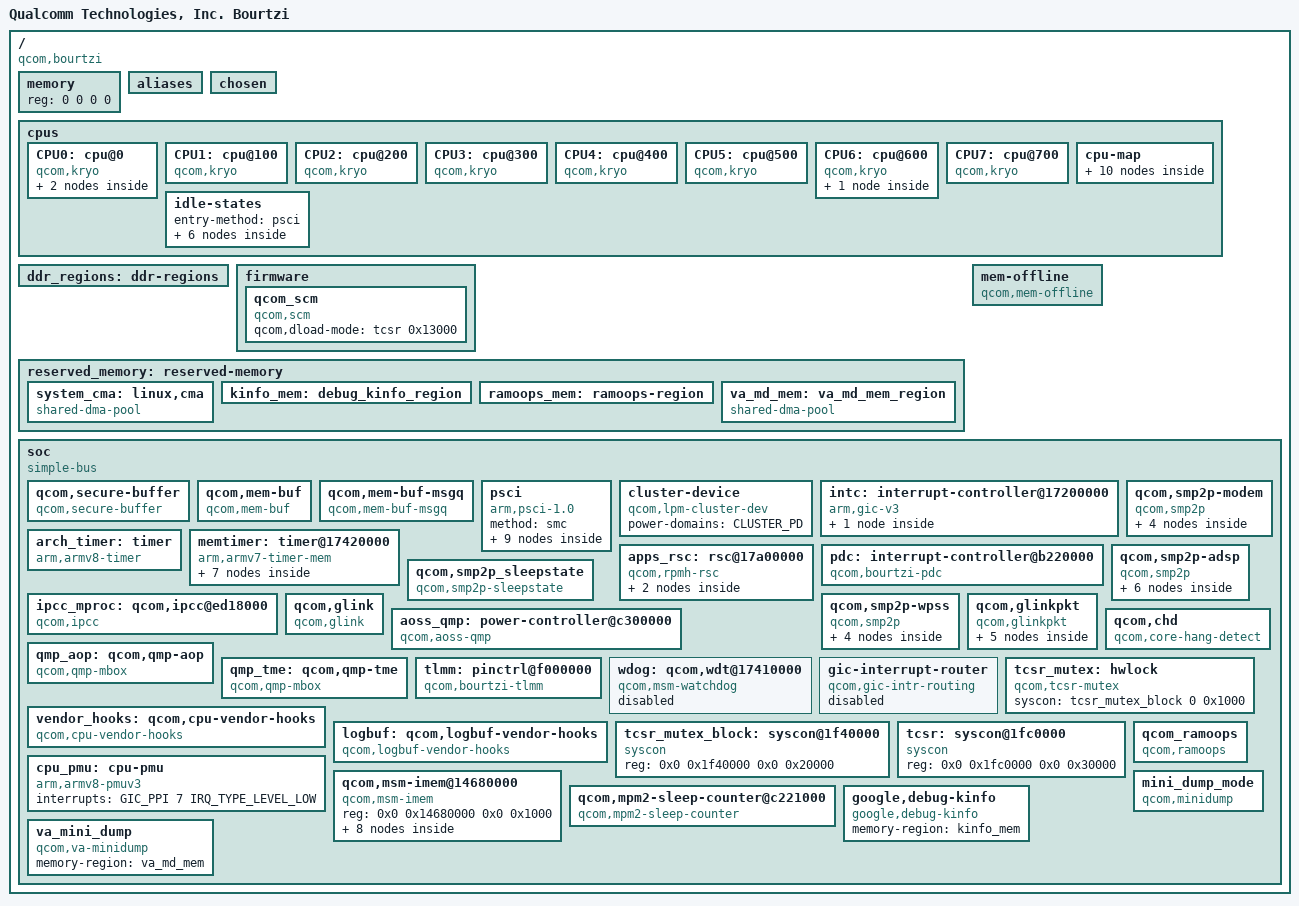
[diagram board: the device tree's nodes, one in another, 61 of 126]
// SPDX-License-Identifier: BSD-3-Clause
/*
 * Copyright (c) Qualcomm Technologies, Inc. and/or its subsidiaries.
 */

#include <dt-bindings/interrupt-controller/arm-gic.h>
#include <dt-bindings/soc/qcom,ipcc.h>
#include <dt-bindings/soc/qcom,rpmh-rsc.h>

/ {
	model = "Qualcomm Technologies, Inc. Bourtzi";
	compatible = "qcom,bourtzi";
	qcom,msm-id = <776 0x10000>;
	interrupt-parent = <&intc>;

	#address-cells = <2>;
	#size-cells = <2>;
	memory { device_type = "memory"; reg = <0 0 0 0>; };

	aliases: aliases { };

	chosen: chosen {
		bootargs = "nokaslr kpti=0 log_buf_len=512K earlycon swiotlb=0 kasan=off cgroup_disable=pressure cgroup.memory=nokmem,nosocket disable_dma32=on page_poison=on restrict_cma_redirect=false no-steal-acc android_arch_task_struct_size=512 sysctl.kernel.sched_pelt_multiplier=4 irqaffinity=0-5 cpufreq.default_governor=performance loop.max_part=7 fw_devlink.strict=1 rcupdate.rcu_expedited=1 rcu_nocbs=0-7 printk.console_no_auto_verbose=1 sysctl.kernel.panic_on_rcu_stall=1 ftrace_dump_on_oops slub_debug=-";
	};

	cpus {
		#address-cells = <2>;
		#size-cells = <0>;

		CPU0: cpu@0 {
			device_type = "cpu";
			compatible = "qcom,kryo";
			reg = <0x0 0x0>;
			capacity-dmips-mhz = <1024>;
			dynamic-power-coefficient = <100>;
			enable-method = "psci";
			cpu-idle-states = <&SILVER_CPU_OFF &SILVER_CPU_RAIL_OFF>;
			power-domains = <&CPU_PD0>;
			power-domain-names = "psci";
			next-level-cache = <&L2_0>;

			L2_0: l2-cache {
				compatible = "arm,arch-cache";
				cache-level = <2>;
				next-level-cache = <&L3_0>;

				L3_0: l3-cache {
					compatible = "arm,arch-cache";
					cache-level = <3>;
				};
			};
		};

		CPU1: cpu@100 {
			device_type = "cpu";
			compatible = "qcom,kryo";
			reg = <0x0 0x100>;
			capacity-dmips-mhz = <1024>;
			dynamic-power-coefficient = <100>;
			enable-method = "psci";
			cpu-idle-states = <&SILVER_CPU_OFF &SILVER_CPU_RAIL_OFF>;
			power-domains = <&CPU_PD1>;
			power-domain-names = "psci";
			next-level-cache = <&L2_0>;
		};

		CPU2: cpu@200 {
			device_type = "cpu";
			compatible = "qcom,kryo";
			reg = <0x0 0x200>;
			capacity-dmips-mhz = <1024>;
			dynamic-power-coefficient = <100>;
			enable-method = "psci";
			cpu-idle-states = <&SILVER_CPU_OFF &SILVER_CPU_RAIL_OFF>;
			power-domains = <&CPU_PD2>;
			power-domain-names = "psci";
			next-level-cache = <&L2_0>;
		};

		CPU3: cpu@300 {
			device_type = "cpu";
			compatible = "qcom,kryo";
			reg = <0x0 0x300>;
			capacity-dmips-mhz = <1024>;
			dynamic-power-coefficient = <100>;
			enable-method = "psci";
			cpu-idle-states = <&SILVER_CPU_OFF &SILVER_CPU_RAIL_OFF>;
			power-domains = <&CPU_PD3>;
			power-domain-names = "psci";
			next-level-cache = <&L2_0>;
		};

		CPU4: cpu@400 {
			device_type = "cpu";
			compatible = "qcom,kryo";
			reg = <0x0 0x400>;
			capacity-dmips-mhz = <1024>;
			dynamic-power-coefficient = <100>;
			enable-method = "psci";
			cpu-idle-states = <&SILVER_CPU_OFF &SILVER_CPU_RAIL_OFF>;
			power-domains = <&CPU_PD4>;
			power-domain-names = "psci";
			next-level-cache = <&L2_0>;
		};

		CPU5: cpu@500 {
			device_type = "cpu";
			compatible = "qcom,kryo";
			reg = <0x0 0x500>;
			capacity-dmips-mhz = <1024>;
			dynamic-power-coefficient = <100>;
			enable-method = "psci";
			cpu-idle-states = <&SILVER_CPU_OFF &SILVER_CPU_RAIL_OFF>;
			power-domains = <&CPU_PD5>;
			power-domain-names = "psci";
			next-level-cache = <&L2_0>;
		};

		CPU6: cpu@600 {
			device_type = "cpu";
			compatible = "qcom,kryo";
			reg = <0x0 0x600>;
			capacity-dmips-mhz = <1945>;
			dynamic-power-coefficient = <483>;
			enable-method = "psci";
			cpu-idle-states = <&GOLD_CPU_OFF &GOLD_CPU_RAIL_OFF>;
			power-domains = <&CPU_PD6>;
			power-domain-names = "psci";
			next-level-cache = <&L2_6>;

			L2_6: l2-cache {
				compatible = "arm,arch-cache";
				cache-level = <2>;
				next-level-cache = <&L3_0>;
			};
		};

		CPU7: cpu@700 {
			device_type = "cpu";
			compatible = "qcom,kryo";
			reg = <0x0 0x700>;
			capacity-dmips-mhz = <1945>;
			dynamic-power-coefficient = <483>;
			enable-method = "psci";
			cpu-idle-states = <&GOLD_CPU_OFF &GOLD_CPU_RAIL_OFF>;
			power-domains = <&CPU_PD7>;
			power-domain-names = "psci";
			next-level-cache = <&L2_6>;
		};

		cpu-map {

			cluster0 {

				core0 {
					cpu = <&CPU0>;
				};

				core1 {
					cpu = <&CPU1>;
				};

				core2 {
					cpu = <&CPU2>;
				};

				core3 {
					cpu = <&CPU3>;
				};

				core4 {
					cpu = <&CPU4>;
				};

				core5 {
					cpu = <&CPU5>;
				};
			};

			cluster1 {

				core0 {
					cpu = <&CPU6>;
				};

				core1 {
					cpu = <&CPU7>;
				};
			};
		};

		idle-states {
			entry-method = "psci";

			SILVER_CPU_OFF: silver-c3 {  /* C3 */
				compatible = "arm,idle-state";
				idle-state-name = "pc";
				entry-latency-us = <350>;
				exit-latency-us = <900>;
				min-residency-us = <1774>;
				arm,psci-suspend-param = <0x40000003>;
				local-timer-stop;
			};

			SILVER_CPU_RAIL_OFF: silver-c4 {  /* C4 */
				compatible = "arm,idle-state";
				idle-state-name = "rail-pc";
				entry-latency-us = <800>;
				exit-latency-us = <750>;
				min-residency-us = <4090>;
				arm,psci-suspend-param = <0x40000004>;
				local-timer-stop;
			};

			GOLD_CPU_OFF: gold-c3 {  /* C3 */
				compatible = "arm,idle-state";
				idle-state-name = "pc";
				entry-latency-us = <400>;
				exit-latency-us = <1550>;
				min-residency-us = <2207>;
				arm,psci-suspend-param = <0x40000003>;
				local-timer-stop;
			};

			GOLD_CPU_RAIL_OFF: gold-c4 {  /* C4 */
				compatible = "arm,idle-state";
				idle-state-name = "rail-pc";
				entry-latency-us = <600>;
				exit-latency-us = <1550>;
				min-residency-us = <4791>;
				arm,psci-suspend-param = <0x40000004>;
				local-timer-stop;
			};

			CLUSTER_OFF: cluster-d4 { /* D4 */
				compatible = "domain-idle-state";
				idle-state-name = "l3-off";
				entry-latency-us = <1050>;
				exit-latency-us = <2500>;
				min-residency-us = <5309>;
				arm,psci-suspend-param = <0x41000044>;
			};

			CX_RET: cx-ret { /* Cx Ret */
				compatible = "domain-idle-state";
				idle-state-name = "cx-ret";
				entry-latency-us = <1561>;
				exit-latency-us = <2801>;
				min-residency-us = <8550>;
				arm,psci-suspend-param = <0x41003344>;
			};
		};
	};

	ddr_regions: ddr-regions { };

	firmware: firmware { };

	reserved_memory: reserved-memory { };

	mem-offline {
		compatible = "qcom,mem-offline";
		offline-sizes = <0x2 0xc0000000 0x1 0x0>;
		granule = <512>;
		qcom,qmp = <&aoss_qmp>;
	};

	soc: soc { };
};

&firmware {
	qcom_scm: qcom_scm {
		compatible = "qcom,scm";
		qcom,dload-mode = <&tcsr 0x13000>;
	};
};

#include "bourtzi-reserved-memory.dtsi"
#include "msm-arm-smmu-bourtzi.dtsi"
#include "bourtzi-dma-heaps.dtsi"

&reserved_memory {
	#address-cells = <2>;
	#size-cells = <2>;
	ranges;

	/* global autoconfigured region for contiguous allocations */
	system_cma: linux,cma {
		compatible = "shared-dma-pool";
		alloc-ranges = <0x0 0x00000000 0x0 0xffffffff>;
		reusable;
		alignment = <0x0 0x400000>;
		size = <0x0 0x2400000>;
		linux,cma-default;
	};

	kinfo_mem: debug_kinfo_region {
		alloc-ranges = <0x0 0x00000000 0xffffffff 0xffffffff>;
		size = <0x0 0x1000>;
		no-map;
	};

	ramoops_mem: ramoops-region {
		alloc-ranges = <0x1 0x00000000 0xfffffffe 0xffffffff>;
		size = <0x0 0x200000>;
		no-map;
	};

	va_md_mem: va_md_mem_region {
		compatible = "shared-dma-pool";
		alloc-ranges = <0x0 0x00000000 0x0 0xffffffff>;
		reusable;
		size = <0 0x1000000>;
	};
};

&soc {
	#address-cells = <2>;
	#size-cells = <2>;
	ranges = <0 0 0 0 0x10 0>;
	compatible = "simple-bus";

	qcom,secure-buffer {
		compatible = "qcom,secure-buffer";
	};

	qcom,mem-buf {
		compatible = "qcom,mem-buf";
		qcom,mem-buf-capabilities = "supplier";
		qcom,vmid = <3>;
	};

	qcom,mem-buf-msgq {
		compatible = "qcom,mem-buf-msgq";
	};

	psci: psci {
		compatible = "arm,psci-1.0";
		method = "smc";

		CPU_PD0: cpu-pd0 {
			#power-domain-cells = <0>;
			power-domains = <&CLUSTER_PD>;
		};

		CPU_PD1: cpu-pd1 {
			#power-domain-cells = <0>;
			power-domains = <&CLUSTER_PD>;
		};

		CPU_PD2: cpu-pd2 {
			#power-domain-cells = <0>;
			power-domains = <&CLUSTER_PD>;
		};

		CPU_PD3: cpu-pd3 {
			#power-domain-cells = <0>;
			power-domains = <&CLUSTER_PD>;
		};

		CPU_PD4: cpu-pd4 {
			#power-domain-cells = <0>;
			power-domains = <&CLUSTER_PD>;
		};

		CPU_PD5: cpu-pd5 {
			#power-domain-cells = <0>;
			power-domains = <&CLUSTER_PD>;
		};

		CPU_PD6: cpu-pd6 {
			#power-domain-cells = <0>;
			power-domains = <&CLUSTER_PD>;
		};

		CPU_PD7: cpu-pd7 {
			#power-domain-cells = <0>;
			power-domains = <&CLUSTER_PD>;
		};

		CLUSTER_PD: cluster-pd {
			#power-domain-cells = <0>;
			domain-idle-states = <&CLUSTER_OFF &CX_RET>;
		};
	};

	cluster-device {
		compatible = "qcom,lpm-cluster-dev";
		power-domains = <&CLUSTER_PD>;
	};

	intc: interrupt-controller@17200000 {
		compatible = "arm,gic-v3";
		#interrupt-cells = <3>;
		interrupt-controller;
		#redistributor-regions = <1>;
		redistributor-stride = <0x0 0x20000>;
		reg = <0x0 0x17200000 0x0 0x10000>,	/* GICD */
		      <0x0 0x17260000 0x0 0x100000>;	/* GICR * 8 */
		interrupts = <GIC_PPI 9 IRQ_TYPE_LEVEL_LOW>;

		#address-cells = <1>;
		#size-cells = <1>;
		ranges;
		gic_its: msi-controller@17240000 {
			compatible = "arm,gic-v3-its";
			msi-controller;
			#msi-cells = <1>;
			reg = <0x17240000 0x20000>;
		};
	};

	arch_timer: timer {
		compatible = "arm,armv8-timer";
		interrupts = <GIC_PPI 13 (GIC_CPU_MASK_SIMPLE(8) | IRQ_TYPE_LEVEL_LOW)>,
			     <GIC_PPI 14 (GIC_CPU_MASK_SIMPLE(8) | IRQ_TYPE_LEVEL_LOW)>,
			     <GIC_PPI 11 (GIC_CPU_MASK_SIMPLE(8) | IRQ_TYPE_LEVEL_LOW)>,
			     <GIC_PPI 10 (GIC_CPU_MASK_SIMPLE(8) | IRQ_TYPE_LEVEL_LOW)>;
		clock-frequency = <19200000>;
	};

	memtimer: timer@17420000 {
		compatible = "arm,armv7-timer-mem";
		reg = <0x0 0x17420000 0x0 0x1000>;
		clock-frequency = <19200000>;
		#address-cells = <1>;
		#size-cells = <1>;
		ranges;

		frame@17421000 {
			frame-number = <0>;
			interrupts = <GIC_SPI 8 IRQ_TYPE_LEVEL_HIGH>,
				     <GIC_SPI 6 IRQ_TYPE_LEVEL_HIGH>;
			reg = <0x17421000 0x1000>,
			      <0x17422000 0x1000>;
		};

		frame@17423000 {
			frame-number = <1>;
			interrupts = <GIC_SPI 9 IRQ_TYPE_LEVEL_HIGH>;
			reg = <0x17423000 0x1000>;
			status = "disabled";
		};

		frame@17425000 {
			frame-number = <2>;
			interrupts = <GIC_SPI 10 IRQ_TYPE_LEVEL_HIGH>;
			reg = <0x17425000 0x1000>;
			status = "disabled";
		};

		frame@17427000 {
			frame-number = <3>;
			interrupts = <GIC_SPI 11 IRQ_TYPE_LEVEL_HIGH>;
			reg = <0x17427000 0x1000>;
			status = "disabled";
		};

		frame@17429000 {
			frame-number = <4>;
			interrupts = <GIC_SPI 12 IRQ_TYPE_LEVEL_HIGH>;
			reg = <0x17429000 0x1000>;
			status = "disabled";
		};

		frame@1742b000 {
			frame-number = <5>;
			interrupts = <GIC_SPI 13 IRQ_TYPE_LEVEL_HIGH>;
			reg = <0x1742b000 0x1000>;
			status = "disabled";
		};

		frame@1742d000 {
			frame-number = <6>;
			interrupts = <GIC_SPI 14 IRQ_TYPE_LEVEL_HIGH>;
			reg = <0x1742d000 0x1000>;
			status = "disabled";
		};
	};

	apps_rsc: rsc@17a00000 {
		label = "apps_rsc";
		compatible = "qcom,rpmh-rsc";
		reg = <0x0 0x17a00000 0x0 0x10000>,
		      <0x0 0x17a10000 0x0 0x10000>,
		      <0x0 0x17a20000 0x0 0x10000>;
		reg-names = "drv-0", "drv-1", "drv-2";
		qcom,drv-count = <3>;
		interrupts = <GIC_SPI 3 IRQ_TYPE_LEVEL_HIGH>,
			     <GIC_SPI 4 IRQ_TYPE_LEVEL_HIGH>,
			     <GIC_SPI 5 IRQ_TYPE_LEVEL_HIGH>;
		power-domains = <&CLUSTER_PD>;

		apps_rsc_drv2: drv@2 {
			qcom,drv-id = <2>;
			qcom,tcs-offset = <0xd00>;
			qcom,tcs-distance = <0x2a0>;

			channel@0 {
				 qcom,tcs-config = <ACTIVE_TCS    2>,
						   <SLEEP_TCS     3>,
						   <WAKE_TCS      3>,
						   <CONTROL_TCS   0>,
						   <FAST_PATH_TCS 0>;
			};
		};
	};

	pdc: interrupt-controller@b220000 {
		compatible = "qcom,bourtzi-pdc", "qcom,pdc";
		reg = <0x0 0xb220000 0x0 0x10000>, <0x0 0x174000f0 0x0 0x64>;
		qcom,pdc-ranges = <0 480 94>, <94 609 31>, <125 63 1>,
				  <126 716 12>;
		#interrupt-cells = <2>;
		interrupt-parent = <&intc>;
		interrupt-controller;
	};

	ipcc_mproc: qcom,ipcc@ed18000 {
		compatible = "qcom,ipcc";
		reg = <0x0 0xed18000 0x0 0x1000>;
		interrupts = <GIC_SPI 229 IRQ_TYPE_LEVEL_HIGH>;
		interrupt-controller;
		#interrupt-cells = <3>;
		#mbox-cells = <2>;
	};

	qcom,smp2p-modem {
		compatible = "qcom,smp2p";
		qcom,smem = <435>, <428>;
		interrupt-parent = <&ipcc_mproc>;
		interrupts = <IPCC_CLIENT_MPSS IPCC_MPROC_SIGNAL_SMP2P
				IRQ_TYPE_EDGE_RISING>;
		mboxes = <&ipcc_mproc IPCC_CLIENT_MPSS IPCC_MPROC_SIGNAL_SMP2P>;
		qcom,local-pid = <0>;
		qcom,remote-pid = <1>;

		modem_smp2p_out: master-kernel {
			qcom,entry-name = "master-kernel";
			#qcom,smem-state-cells = <1>;
		};

		modem_smp2p_in: slave-kernel {
			qcom,entry-name = "slave-kernel";
			interrupt-controller;
			#interrupt-cells = <2>;
		};

		smp2p_ipa_1_out: qcom,smp2p-ipa-1-out {
			qcom,entry-name = "ipa";
			#qcom,smem-state-cells = <1>;
		};

		/* ipa - inbound entry from mss */
		smp2p_ipa_1_in: qcom,smp2p-ipa-1-in {
			qcom,entry-name = "ipa";
			interrupt-controller;
			#interrupt-cells = <2>;
		};
	};

	qcom,smp2p-adsp {
		compatible = "qcom,smp2p";
		qcom,smem = <443>, <429>;
		interrupt-parent = <&ipcc_mproc>;
		interrupts = <IPCC_CLIENT_LPASS IPCC_MPROC_SIGNAL_SMP2P
			      IRQ_TYPE_EDGE_RISING>;
		mboxes = <&ipcc_mproc IPCC_CLIENT_LPASS
			  IPCC_MPROC_SIGNAL_SMP2P>;
		qcom,local-pid = <0>;
		qcom,remote-pid = <2>;

		adsp_smp2p_out: master-kernel {
			qcom,entry-name = "master-kernel";
			#qcom,smem-state-cells = <1>;
		};

		adsp_smp2p_in: slave-kernel {
			qcom,entry-name = "slave-kernel";
			interrupt-controller;
			#interrupt-cells = <2>;
		};

		sleepstate_smp2p_out: sleepstate-out {
			qcom,entry-name = "sleepstate";
			#qcom,smem-state-cells = <1>;
		};

		sleepstate_smp2p_in: qcom,sleepstate-in {
			qcom,entry-name = "sleepstate_see";
			interrupt-controller;
			#interrupt-cells = <2>;
		};

		smp2p_rdbg2_out: qcom,smp2p-rdbg2-out {
			qcom,entry-name = "rdbg";
			#qcom,smem-state-cells = <1>;
		};

		smp2p_rdbg2_in: qcom,smp2p-rdbg2-in {
			qcom,entry-name = "rdbg";
			interrupt-controller;
			#interrupt-cells = <2>;
		};
	};

	qcom,smp2p_sleepstate {
		compatible = "qcom,smp2p-sleepstate";
		qcom,smem-states = <&sleepstate_smp2p_out 0>;
		interrupt-parent = <&sleepstate_smp2p_in>;
		interrupts = <0 0>;
		interrupt-names = "smp2p-sleepstate-in";
	};

	qcom,smp2p-wpss {
		compatible = "qcom,smp2p";
		qcom,smem = <617>, <616>;
		interrupt-parent = <&ipcc_mproc>;
		interrupts = <IPCC_CLIENT_WPSS IPCC_MPROC_SIGNAL_SMP2P
			IRQ_TYPE_EDGE_RISING>;
		mboxes = <&ipcc_mproc IPCC_CLIENT_WPSS IPCC_MPROC_SIGNAL_SMP2P>;
		qcom,local-pid = <0>;
		qcom,remote-pid = <13>;

		wpss_smp2p_out: master-kernel {
			qcom,entry-name = "master-kernel";
			#qcom,smem-state-cells = <1>;
		};

		wpss_smp2p_in: slave-kernel {
			qcom,entry-name = "slave-kernel";
			interrupt-controller;
			#interrupt-cells = <2>;
		};

		smp2p_wlan_1_in: qcom,smp2p-wlan-1-in {
			qcom,entry-name = "wlan";
			interrupt-controller;
			#interrupt-cells = <2>;
		};

		smp2p_wlan_1_out: qcom,smp2p-wlan-1-out {
			qcom,entry-name = "wlan";
			#qcom,smem-state-cells = <1>;
		};
	};

	qcom,glinkpkt {
		compatible = "qcom,glinkpkt";

		qcom,glinkpkt-at-mdm0 {
			qcom,glinkpkt-edge = "mpss";
			qcom,glinkpkt-ch-name = "DS";
			qcom,glinkpkt-dev-name = "at_mdm0";
		};

		qcom,glinkpkt-data40-cntl {
			qcom,glinkpkt-edge = "mpss";
			qcom,glinkpkt-ch-name = "DATA40_CNTL";
			qcom,glinkpkt-dev-name = "smdcntl8";
		};

		qcom,glinkpkt-data1 {
			qcom,glinkpkt-edge = "mpss";
			qcom,glinkpkt-ch-name = "DATA1";
			qcom,glinkpkt-dev-name = "smd7";
		};

		qcom,glinkpkt-data4 {
			qcom,glinkpkt-edge = "mpss";
			qcom,glinkpkt-ch-name = "DATA4";
			qcom,glinkpkt-dev-name = "smd8";
		};

		qcom,glinkpkt-data11 {
			qcom,glinkpkt-edge = "mpss";
			qcom,glinkpkt-ch-name = "DATA11";
			qcom,glinkpkt-dev-name = "smd11";
		};
	};

	qcom,glink {
		compatible = "qcom,glink";
	};

	aoss_qmp: power-controller@c300000 {
		compatible = "qcom,aoss-qmp";
		reg = <0x0 0xc300000 0x0 0x400>;
		interrupt-parent = <&ipcc_mproc>;
		interrupts = <IPCC_CLIENT_AOP
			IPCC_MPROC_SIGNAL_GLINK_QMP
			IRQ_TYPE_EDGE_RISING>;
		mboxes = <&ipcc_mproc IPCC_CLIENT_AOP
			IPCC_MPROC_SIGNAL_GLINK_QMP>;

		#power-domain-cells = <1>;
		#clock-cells = <0>;
	};

	qmp_aop: qcom,qmp-aop {
		compatible = "qcom,qmp-mbox";
		qcom,qmp = <&aoss_qmp>;
		label = "aop";
		#mbox-cells = <1>;
	};

	qmp_tme: qcom,qmp-tme {
		compatible = "qcom,qmp-mbox";
		qcom,remote-pid = <14>;
		mboxes = <&ipcc_mproc IPCC_CLIENT_TME
				IPCC_MPROC_SIGNAL_GLINK_QMP>;
		mbox-names = "tme_qmp";
		interrupt-parent = <&ipcc_mproc>;
		interrupts = <IPCC_CLIENT_TME
				IPCC_MPROC_SIGNAL_GLINK_QMP
				IRQ_TYPE_EDGE_RISING>;

		label = "tme";
		qcom,early-boot;
		priority = <0>;
		mbox-desc-offset = <0x0>;
		#mbox-cells = <1>;
	};

	tlmm: pinctrl@f000000 {
		compatible = "qcom,bourtzi-tlmm";
		reg = <0x0 0xf000000 0x0 0x1000000>;
		gpio-controller;
		#gpio-cells = <2>;
		interrupt-controller;
		#interrupt-cells = <2>;
		interrupts = <GIC_SPI 208 IRQ_TYPE_LEVEL_HIGH>;
		wakeup-parent = <&pdc>;
		/* TODO: Add qcom,gpios-reserved */
	};

	wdog: qcom,wdt@17410000 {
		compatible = "qcom,msm-watchdog";
		reg = <0x0 0x17410000 0x0 0x1000>;
		reg-names = "wdt-base";
		interrupts = <GIC_SPI 0 IRQ_TYPE_LEVEL_HIGH>,
			     <GIC_SPI 1 IRQ_TYPE_LEVEL_HIGH>;
		qcom,bark-time = <11000>;
		qcom,pet-time = <9360>;
		qcom,ipi-ping;
		qcom,wakeup-enable;
		status = "disabled";
	};

	gic-interrupt-router {
		compatible = "qcom,gic-intr-routing";
		/* keep few silver/m cores in class0 only to avoid wakeup of gold/l cores */
		qcom,gic-class0-cpus = <&CPU0 &CPU1 &CPU2 &CPU3 &CPU4 &CPU5>;
		/* keep gold/l cores in class1 */
		qcom,gic-class1-cpus = <&CPU6 &CPU7>;
		qcom,gic-cpulist = <&CPU0 &CPU1 &CPU2 &CPU3 &CPU4 &CPU5 &CPU6 &CPU7>;
		qcom,gic-runtime-cpu-class-en;
		status = "disabled";
	};

	vendor_hooks: qcom,cpu-vendor-hooks {
		compatible = "qcom,cpu-vendor-hooks";
	};

	logbuf: qcom,logbuf-vendor-hooks {
		compatible = "qcom,logbuf-vendor-hooks";
	};

	qcom,chd {
		compatible = "qcom,core-hang-detect";
		label = "core";
		qcom,chd-percpu-info = <&CPU0 0x17800058 0x17800060>,
				<&CPU1 0x17810058 0x17810060>,
				<&CPU2 0x17820058 0x17820060>,
				<&CPU3 0x17830058 0x17830060>,
				<&CPU4 0x17840058 0x17840060>,
				<&CPU5 0x17850058 0x17850060>,
				<&CPU6 0x17860058 0x17860060>,
				<&CPU7 0x17870058 0x17870060>;
	};

	tcsr_mutex_block: syscon@1f40000 {
		compatible = "syscon";
		reg = <0x0 0x1f40000 0x0 0x20000>;
	};

	tcsr_mutex: hwlock {
		compatible = "qcom,tcsr-mutex";
		syscon = <&tcsr_mutex_block 0 0x1000>;
		#hwlock-cells = <1>;
	};

	tcsr: syscon@1fc0000 {
		compatible = "syscon";
		reg = <0x0 0x1fc0000 0x0 0x30000>;
		/* TODO: Make sure dload mode is updated in qcom_scm node */
	};

	cpu_pmu: cpu-pmu {
		compatible = "arm,armv8-pmuv3";
		interrupts = <GIC_PPI 7 IRQ_TYPE_LEVEL_LOW>;
	};

	qcom,msm-imem@14680000 {
		compatible = "qcom,msm-imem";
		reg = <0x0 0x14680000 0x0 0x1000>;
		ranges = <0x0 0x0 0x14680000 0x1000>;
		#address-cells = <1>;
		#size-cells = <1>;

		mem_dump_table@10 {
			compatible = "qcom,msm-imem-mem_dump_table";
			reg = <0x10 0x8>;
		};

		restart_reason@65c {
			compatible = "qcom,msm-imem-restart_reason";
			reg = <0x65c 0x4>;
		};

		dload_type@1c {
			compatible = "qcom,msm-imem-dload-type";
			reg = <0x1c 0x4>;
		};

		boot_stats@6b0 {
			compatible = "qcom,msm-imem-boot_stats";
			reg = <0x6b0 0x20>;
		};

		kaslr_offset@6d0 {
			compatible = "qcom,msm-imem-kaslr_offset";
			reg = <0x6d0 0xc>;
		};

		pil@94c {
			compatible = "qcom,pil-reloc-info";
			reg = <0x94c 0xc8>;
		};

		pil@6dc {
			compatible = "qcom,msm-imem-pil-disable-timeout";
			reg = <0x6dc 0x4>;
		};

		diag_dload@c8 {
			compatible = "qcom,msm-imem-diag-dload";
			reg = <0xc8 0xc8>;
		};
	};

	qcom,mpm2-sleep-counter@c221000 {
		compatible = "qcom,mpm2-sleep-counter";
		reg = <0x0 0xc221000 0x0 0x1000>;
		clock-frequency = <32768>;
	};

	google,debug-kinfo {
		compatible = "google,debug-kinfo";
		memory-region = <&kinfo_mem>;
	};

	qcom_ramoops {
		compatible = "qcom,ramoops";
		memory-region = <&ramoops_mem>;
		pmsg-size = <0x200000>;
		mem-type = <2>;
	};

	mini_dump_mode {
		compatible = "qcom,minidump";
	};

	va_mini_dump {
		compatible = "qcom,va-minidump";
		memory-region = <&va_md_mem>;
	};
};

#include "bourtzi-pinctrl.dtsi"
#include "bourtzi-walt.dtsi"
#include "bourtzi-usb.dtsi"
